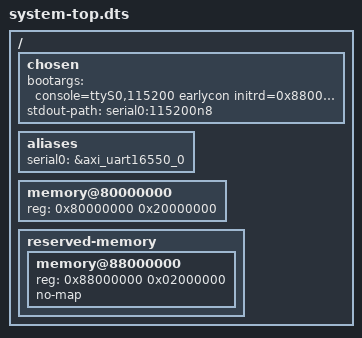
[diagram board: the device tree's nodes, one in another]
/*
 * CAUTION: This file is automatically generated by Xilinx.
 * Version: XSCT 2021.1
 * Today is: Sat Jan 15 06:48:48 2022
 */


/dts-v1/;
#include "pl.dtsi"
/ {
	chosen {
		//bootargs = "console=ttyS0,115200 earlycon earlyprintk phram.phram=rootfs,0x84000000,0x2000000 root=/dev/mtdblock0";
		bootargs = "console=ttyS0,115200 earlycon initrd=0x88000000,3100058";
		stdout-path = "serial0:115200n8";
	};
	aliases {
		serial0 = &axi_uart16550_0;
	};
	// reserved-memory {
    //     #address-cells = <1>;
    //     #size-cells = <1>;
    //     ranges;
    //     sbi_memory: sbi_memory@80000000 {
    //         reg = <0x80000000 0x100000>;
    //     };
    // };
	memory@80000000 {
		device_type = "memory";
		reg = <0x80000000 0x20000000>;
	};
	reserved-memory {
			#address-cells = <1>;
			#size-cells = <1>;
			ranges;
			memory@88000000 {
					reg = <0x88000000 0x02000000>;
					no-map;
			};
	};
};
